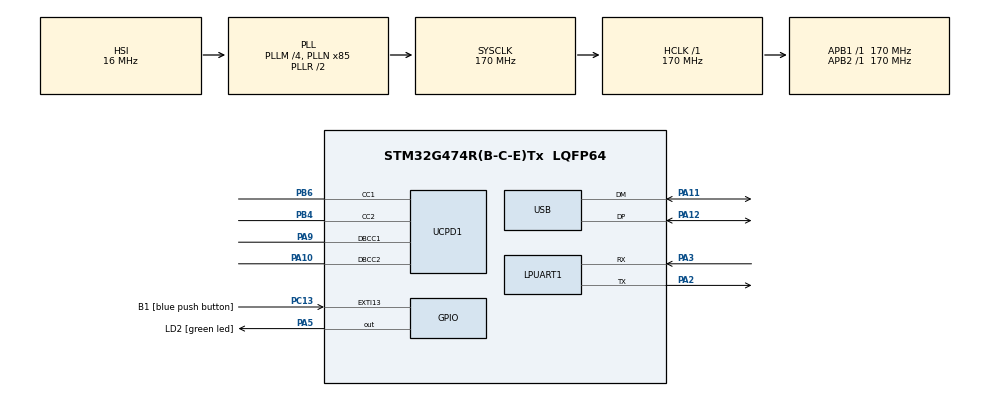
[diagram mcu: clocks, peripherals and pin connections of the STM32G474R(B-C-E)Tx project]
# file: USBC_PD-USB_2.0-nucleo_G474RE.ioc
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Dma.LPUART1_RX.3.Direction=DMA_PERIPH_TO_MEMORY
Dma.LPUART1_RX.3.EventEnable=DISABLE
Dma.LPUART1_RX.3.Instance=DMA1_Channel4
Dma.LPUART1_RX.3.MemDataAlignment=DMA_MDATAALIGN_BYTE
Dma.LPUART1_RX.3.MemInc=DMA_MINC_ENABLE
Dma.LPUART1_RX.3.Mode=DMA_NORMAL
Dma.LPUART1_RX.3.PeriphDataAlignment=DMA_PDATAALIGN_BYTE
Dma.LPUART1_RX.3.PeriphInc=DMA_PINC_DISABLE
Dma.LPUART1_RX.3.Polarity=HAL_DMAMUX_REQ_GEN_RISING
Dma.LPUART1_RX.3.Priority=DMA_PRIORITY_LOW
Dma.LPUART1_RX.3.RequestNumber=1
Dma.LPUART1_RX.3.SignalID=NONE
Dma.LPUART1_RX.3.SyncEnable=DISABLE
Dma.LPUART1_RX.3.SyncPolarity=HAL_DMAMUX_SYNC_NO_EVENT
Dma.LPUART1_RX.3.SyncRequestNumber=1
Dma.LPUART1_RX.3.SyncSignalID=NONE
Dma.LPUART1_TX.2.Direction=DMA_MEMORY_TO_PERIPH
Dma.LPUART1_TX.2.EventEnable=DISABLE
Dma.LPUART1_TX.2.Instance=DMA1_Channel3
Dma.LPUART1_TX.2.MemDataAlignment=DMA_MDATAALIGN_BYTE
Dma.LPUART1_TX.2.MemInc=DMA_MINC_ENABLE
Dma.LPUART1_TX.2.Mode=DMA_NORMAL
Dma.LPUART1_TX.2.PeriphDataAlignment=DMA_PDATAALIGN_BYTE
Dma.LPUART1_TX.2.PeriphInc=DMA_PINC_DISABLE
Dma.LPUART1_TX.2.Polarity=HAL_DMAMUX_REQ_GEN_RISING
Dma.LPUART1_TX.2.Priority=DMA_PRIORITY_LOW
Dma.LPUART1_TX.2.RequestNumber=1
Dma.LPUART1_TX.2.SignalID=NONE
Dma.LPUART1_TX.2.SyncEnable=DISABLE
Dma.LPUART1_TX.2.SyncPolarity=HAL_DMAMUX_SYNC_NO_EVENT
Dma.LPUART1_TX.2.SyncRequestNumber=1
Dma.LPUART1_TX.2.SyncSignalID=NONE
Dma.Request0=UCPD1_RX
Dma.Request1=UCPD1_TX
Dma.Request2=LPUART1_TX
Dma.Request3=LPUART1_RX
Dma.UCPD1_RX.0.Direction=DMA_PERIPH_TO_MEMORY
Dma.UCPD1_RX.0.EventEnable=DISABLE
Dma.UCPD1_RX.0.Instance=DMA1_Channel1
Dma.UCPD1_RX.0.MemDataAlignment=DMA_MDATAALIGN_BYTE
Dma.UCPD1_RX.0.MemInc=DMA_MINC_ENABLE
Dma.UCPD1_RX.0.Mode=DMA_NORMAL
Dma.UCPD1_RX.0.PeriphDataAlignment=DMA_PDATAALIGN_BYTE
Dma.UCPD1_RX.0.PeriphInc=DMA_PINC_DISABLE
Dma.UCPD1_RX.0.Polarity=HAL_DMAMUX_REQ_GEN_RISING
Dma.UCPD1_RX.0.Priority=DMA_PRIORITY_LOW
Dma.UCPD1_RX.0.RequestNumber=1
Dma.UCPD1_RX.0.SignalID=NONE
Dma.UCPD1_RX.0.SyncEnable=DISABLE
Dma.UCPD1_RX.0.SyncPolarity=HAL_DMAMUX_SYNC_NO_EVENT
Dma.UCPD1_RX.0.SyncRequestNumber=1
Dma.UCPD1_RX.0.SyncSignalID=NONE
Dma.UCPD1_TX.1.Direction=DMA_MEMORY_TO_PERIPH
Dma.UCPD1_TX.1.EventEnable=DISABLE
Dma.UCPD1_TX.1.Instance=DMA1_Channel2
Dma.UCPD1_TX.1.MemDataAlignment=DMA_MDATAALIGN_BYTE
Dma.UCPD1_TX.1.MemInc=DMA_MINC_ENABLE
Dma.UCPD1_TX.1.Mode=DMA_NORMAL
Dma.UCPD1_TX.1.PeriphDataAlignment=DMA_PDATAALIGN_BYTE
Dma.UCPD1_TX.1.PeriphInc=DMA_PINC_DISABLE
Dma.UCPD1_TX.1.Polarity=HAL_DMAMUX_REQ_GEN_RISING
Dma.UCPD1_TX.1.Priority=DMA_PRIORITY_LOW
Dma.UCPD1_TX.1.RequestNumber=1
Dma.UCPD1_TX.1.SignalID=NONE
Dma.UCPD1_TX.1.SyncEnable=DISABLE
Dma.UCPD1_TX.1.SyncPolarity=HAL_DMAMUX_SYNC_NO_EVENT
Dma.UCPD1_TX.1.SyncRequestNumber=1
Dma.UCPD1_TX.1.SyncSignalID=NONE
FREERTOS.Tasks01=defaultTask,24,128,StartDefaultTask,Default,NULL,Dynamic,NULL,NULL
FREERTOS.configLIBRARY_MAX_SYSCALL_INTERRUPT_PRIORITY=3
FREERTOS.configTOTAL_HEAP_SIZE=6144
FREERTOS.configUSE_NEWLIB_REENTRANT=1
GUI_INTERFACE.HWBoardVersionName=G474RE
GUI_INTERFACE.PDTypeName=Sink
Mcu.Family=STM32G4
Mcu.Name=STM32G474R(B-C-E)Tx
Mcu.Package=LQFP64
NVIC.DMA1_Channel1_IRQn=true\:3\:0\:false\:false\:true\:true\:false\:true
NVIC.DMA1_Channel2_IRQn=true\:3\:0\:false\:false\:true\:true\:false\:true
NVIC.DMA1_Channel3_IRQn=true\:3\:0\:false\:false\:true\:true\:false\:true
NVIC.DMA1_Channel4_IRQn=true\:3\:0\:false\:false\:true\:true\:false\:true
NVIC.EXTI15_10_IRQn=true\:3\:0\:false\:false\:true\:true\:true\:true
NVIC.LPUART1_IRQn=true\:3\:0\:false\:false\:true\:true\:true\:true
NVIC.PriorityGroup=NVIC_PRIORITYGROUP_4
NVIC.TIM6_DAC_IRQn=true\:4\:0\:true\:false\:true\:false\:false\:true
NVIC.TimeBase=TIM6_DAC_IRQn
NVIC.TimeBaseIP=TIM6
NVIC.UCPD1_IRQn=true\:3\:0\:false\:false\:true\:true\:true\:false
NVIC.USB_HP_IRQn=true\:3\:0\:false\:false\:true\:true\:true\:true
NVIC.USB_LP_IRQn=true\:3\:0\:false\:false\:true\:true\:false\:true
PA10.Mode=EnableDeadBattery
PA10.Signal=UCPD1_DBCC2
PA11.Mode=Device
PA11.Signal=USB_DM
PA12.Mode=Device
PA12.Signal=USB_DP
PA13.GPIO_Label=T_SWDIO
PA13.Mode=Serial_Wire
PA13.Signal=SYS_JTMS-SWDIO
PA14.GPIO_Label=T_SWCLK
PA14.Mode=Serial_Wire
PA14.Signal=SYS_JTCK-SWCLK
PA2.GPIO_Mode=GPIO_MODE_AF_PP
PA2.GPIO_PuPd=GPIO_NOPULL
PA2.GPIO_Speed=GPIO_SPEED_FREQ_LOW
PA2.Mode=Asynchronous
PA2.Signal=LPUART1_TX
PA3.GPIO_Mode=GPIO_MODE_AF_PP
PA3.GPIO_PuPd=GPIO_NOPULL
PA3.GPIO_Speed=GPIO_SPEED_FREQ_LOW
PA3.Mode=Asynchronous
PA3.Signal=LPUART1_RX
PA5.GPIO_Label=LD2 [green led]
PA5.Signal=GPIO_Output
PA9.Mode=EnableDeadBattery
PA9.Signal=UCPD1_DBCC1
PB3.GPIO_Label=T_SWO
PB3.Signal=SYS_JTDO-SWO
PB4.Mode=Sink_AllSignals
PB4.Signal=UCPD1_CC2
PB6.Mode=Sink_AllSignals
PB6.Signal=UCPD1_CC1
PC13.GPIO_Label=B1 [blue push button]
PC13.Signal=GPXTI13
PC14-OSC32_IN.Mode=LSE-External-Oscillator
PC14-OSC32_IN.Signal=RCC_OSC32_IN
PC15-OSC32_OUT.Mode=LSE-External-Oscillator
PC15-OSC32_OUT.Signal=RCC_OSC32_OUT
PF0-OSC_IN.Mode=HSE-External-Oscillator
PF0-OSC_IN.Signal=RCC_OSC_IN
PF1-OSC_OUT.Mode=HSE-External-Oscillator
PF1-OSC_OUT.Signal=RCC_OSC_OUT
ProjectManager.HeapSize=0x500
ProjectManager.StackSize=0x400
ProjectManager.TargetToolchain=STM32CubeIDE
RCC.ADC12Freq_Value=170000000
RCC.ADC345Freq_Value=170000000
RCC.AHBFreq_Value=170000000
RCC.APB1Freq_Value=170000000
RCC.APB1TimFreq_Value=170000000
RCC.APB2Freq_Value=170000000
RCC.APB2TimFreq_Value=170000000
RCC.CK48CLockSelection=RCC_USBCLKSOURCE_HSI48
RCC.CortexFreq_Value=170000000
RCC.EXTERNAL_CLOCK_VALUE=12288000
RCC.HCLKFreq_Value=170000000
RCC.HSE_VALUE=24000000
RCC.HSI48_VALUE=48000000
RCC.HSI_VALUE=16000000
RCC.PLLM=RCC_PLLM_DIV4
RCC.PLLN=85
RCC.RTCClockSelection=RCC_RTCCLKSOURCE_LSE
RCC.SYSCLKFreq_VALUE=170000000
RCC.SYSCLKSource=RCC_SYSCLKSOURCE_PLLCLK
RCC.USBFreq_Value=48000000
RCC.VCOOutputFreq_Value=340000000
USBPD.Is_GetStatus_Supported_P0=USBPD_FALSE
USBPD.PE_SpecRevision_P0=USBPD_SPECIFICATION_REV3
USB_DEVICE.CLASS_NAME_FS=CDC
USB_DEVICE.VirtualMode=Cdc
USB_DEVICE.VirtualModeFS=Cdc_FS
VP_FREERTOS_VS_CMSIS_V2.Mode=CMSIS_V2
VP_GUI_INTERFACE_VS_gui_interface.Mode=GUI_INTERFACE
VP_SYS_VS_DBSignals.Mode=DisableDeadBatterySignals
VP_SYS_VS_tim6.Mode=TIM6
VP_TRACER_EMB_VS_traceremb_lpuart1.Mode=TRACER_EMB_LPUART1
VP_USBPD_VS_PD3FULL.Mode=PD3_Full_Stack
VP_USBPD_VS_USBPD1.Mode=USBPD_P0
VP_USBPD_VS_usbpd_tim1.Mode=TIM1
VP_USBPD_VS_usbpd_traceremb.Mode=TRACER_EMB
VP_USB_DEVICE_VS_USB_DEVICE_CDC_FS.Mode=CDC_FS
board=NUCLEO-G474RE

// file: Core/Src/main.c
/* USER CODE BEGIN Header */
/**
  ******************************************************************************
  * @file           : main.c
  * @brief          : Main program body
  ******************************************************************************
  * @attention
  *
  * <h2><center>&copy; Copyright (c) 2021 STMicroelectronics.
  * All rights reserved.</center></h2>
  *
  * This software component is licensed by ST under BSD 3-Clause license,
  * the "License"; You may not use this file except in compliance with the
  * License. You may obtain a copy of the License at:
  *                        opensource.org/licenses/BSD-3-Clause
  *
  ******************************************************************************
  */
/* USER CODE END Header */
#include "main.h"
#include "cmsis_os.h"
#include "usbpd.h"
#include "usb_device.h"
#include "usb_device.h"

/* USER CODE BEGIN Includes */

#include "usbd_cdc_if.h"

/* USER CODE END Includes */

/* Definitions for defaultTask */
osThreadId_t defaultTaskHandle;
const osThreadAttr_t defaultTask_attributes = {
  .name = "defaultTask",
  .priority = (osPriority_t) osPriorityNormal,
  .stack_size = 128 * 4
};

void SystemClock_Config(void);
static void MX_GPIO_Init(void);
static void MX_LPUART1_UART_Init(void);
static void MX_DMA_Init(void);
static void MX_UCPD1_Init(void);
void StartDefaultTask(void *argument);

int main(void)
{

  /* MCU Configuration--------------------------------------------------------*/

  /* Reset of all peripherals, Initializes the Flash interface and the Systick. */
  HAL_Init();

  /* Configure the system clock */
  SystemClock_Config();

  /* Initialize all configured peripherals */
  MX_GPIO_Init();
  MX_LPUART1_UART_Init();
  MX_DMA_Init();
  MX_UCPD1_Init();
  MX_USB_Device_Init();

  /* Init scheduler */
  osKernelInitialize();
  /* USBPD initialisation ---------------------------------*/
  MX_USBPD_Init();

  /* Create the thread(s) */
  /* creation of defaultTask */
  defaultTaskHandle = osThreadNew(StartDefaultTask, NULL, &defaultTask_attributes);

  /* Start scheduler */
  osKernelStart();

  /* We should never get here as control is now taken by the scheduler */
  /* Infinite loop */
  while (1)
  {

  }
}

void SystemClock_Config(void)
{
  RCC_OscInitTypeDef RCC_OscInitStruct = {0};
  RCC_ClkInitTypeDef RCC_ClkInitStruct = {0};
  RCC_PeriphCLKInitTypeDef PeriphClkInit = {0};

  /** Configure the main internal regulator output voltage
  */
  HAL_PWREx_ControlVoltageScaling(PWR_REGULATOR_VOLTAGE_SCALE1_BOOST);
  /** Initializes the RCC Oscillators according to the specified parameters
  * in the RCC_OscInitTypeDef structure.
  */
  RCC_OscInitStruct.OscillatorType = RCC_OSCILLATORTYPE_HSI|RCC_OSCILLATORTYPE_HSI48;
  RCC_OscInitStruct.HSIState = RCC_HSI_ON;
  RCC_OscInitStruct.HSICalibrationValue = RCC_HSICALIBRATION_DEFAULT;
  RCC_OscInitStruct.HSI48State = RCC_HSI48_ON;
  RCC_OscInitStruct.PLL.PLLState = RCC_PLL_ON;
  RCC_OscInitStruct.PLL.PLLSource = RCC_PLLSOURCE_HSI;
  RCC_OscInitStruct.PLL.PLLM = RCC_PLLM_DIV4;
  RCC_OscInitStruct.PLL.PLLN = 85;
  RCC_OscInitStruct.PLL.PLLP = RCC_PLLP_DIV2;
  RCC_OscInitStruct.PLL.PLLQ = RCC_PLLQ_DIV2;
  RCC_OscInitStruct.PLL.PLLR = RCC_PLLR_DIV2;
  if (HAL_RCC_OscConfig(&RCC_OscInitStruct) != HAL_OK)
  {
    Error_Handler();
  }
  /** Initializes the CPU, AHB and APB buses clocks
  */
  RCC_ClkInitStruct.ClockType = RCC_CLOCKTYPE_HCLK|RCC_CLOCKTYPE_SYSCLK
                              |RCC_CLOCKTYPE_PCLK1|RCC_CLOCKTYPE_PCLK2;
  RCC_ClkInitStruct.SYSCLKSource = RCC_SYSCLKSOURCE_PLLCLK;
  RCC_ClkInitStruct.AHBCLKDivider = RCC_SYSCLK_DIV1;
  RCC_ClkInitStruct.APB1CLKDivider = RCC_HCLK_DIV1;
  RCC_ClkInitStruct.APB2CLKDivider = RCC_HCLK_DIV1;

  if (HAL_RCC_ClockConfig(&RCC_ClkInitStruct, FLASH_LATENCY_4) != HAL_OK)
  {
    Error_Handler();
  }
  /** Initializes the peripherals clocks
  */
  PeriphClkInit.PeriphClockSelection = RCC_PERIPHCLK_LPUART1|RCC_PERIPHCLK_USB;
  PeriphClkInit.Lpuart1ClockSelection = RCC_LPUART1CLKSOURCE_PCLK1;
  PeriphClkInit.UsbClockSelection = RCC_USBCLKSOURCE_HSI48;
  if (HAL_RCCEx_PeriphCLKConfig(&PeriphClkInit) != HAL_OK)
  {
    Error_Handler();
  }
}

static void MX_LPUART1_UART_Init(void)
{

  LL_LPUART_InitTypeDef LPUART_InitStruct = {0};

  LL_GPIO_InitTypeDef GPIO_InitStruct = {0};

  /* Peripheral clock enable */
  LL_APB1_GRP2_EnableClock(LL_APB1_GRP2_PERIPH_LPUART1);

  LL_AHB2_GRP1_EnableClock(LL_AHB2_GRP1_PERIPH_GPIOA);
  /**LPUART1 GPIO Configuration
  PA2   ------> LPUART1_TX
  PA3   ------> LPUART1_RX
  */
  GPIO_InitStruct.Pin = LL_GPIO_PIN_2;
  GPIO_InitStruct.Mode = LL_GPIO_MODE_ALTERNATE;
  GPIO_InitStruct.Speed = LL_GPIO_SPEED_FREQ_LOW;
  GPIO_InitStruct.OutputType = LL_GPIO_OUTPUT_PUSHPULL;
  GPIO_InitStruct.Pull = LL_GPIO_PULL_NO;
  GPIO_InitStruct.Alternate = LL_GPIO_AF_12;
  LL_GPIO_Init(GPIOA, &GPIO_InitStruct);

  GPIO_InitStruct.Pin = LL_GPIO_PIN_3;
  GPIO_InitStruct.Mode = LL_GPIO_MODE_ALTERNATE;
  GPIO_InitStruct.Speed = LL_GPIO_SPEED_FREQ_LOW;
  GPIO_InitStruct.OutputType = LL_GPIO_OUTPUT_PUSHPULL;
  GPIO_InitStruct.Pull = LL_GPIO_PULL_NO;
  GPIO_InitStruct.Alternate = LL_GPIO_AF_12;
  LL_GPIO_Init(GPIOA, &GPIO_InitStruct);

  /* LPUART1 DMA Init */

  /* LPUART1_TX Init */
  LL_DMA_SetPeriphRequest(DMA1, LL_DMA_CHANNEL_3, LL_DMAMUX_REQ_LPUART1_TX);

  LL_DMA_SetDataTransferDirection(DMA1, LL_DMA_CHANNEL_3, LL_DMA_DIRECTION_MEMORY_TO_PERIPH);

  LL_DMA_SetChannelPriorityLevel(DMA1, LL_DMA_CHANNEL_3, LL_DMA_PRIORITY_LOW);

  LL_DMA_SetMode(DMA1, LL_DMA_CHANNEL_3, LL_DMA_MODE_NORMAL);

  LL_DMA_SetPeriphIncMode(DMA1, LL_DMA_CHANNEL_3, LL_DMA_PERIPH_NOINCREMENT);

  LL_DMA_SetMemoryIncMode(DMA1, LL_DMA_CHANNEL_3, LL_DMA_MEMORY_INCREMENT);

  LL_DMA_SetPeriphSize(DMA1, LL_DMA_CHANNEL_3, LL_DMA_PDATAALIGN_BYTE);

  LL_DMA_SetMemorySize(DMA1, LL_DMA_CHANNEL_3, LL_DMA_MDATAALIGN_BYTE);

  /* LPUART1_RX Init */
  LL_DMA_SetPeriphRequest(DMA1, LL_DMA_CHANNEL_4, LL_DMAMUX_REQ_LPUART1_RX);

  LL_DMA_SetDataTransferDirection(DMA1, LL_DMA_CHANNEL_4, LL_DMA_DIRECTION_PERIPH_TO_MEMORY);

  LL_DMA_SetChannelPriorityLevel(DMA1, LL_DMA_CHANNEL_4, LL_DMA_PRIORITY_LOW);

  LL_DMA_SetMode(DMA1, LL_DMA_CHANNEL_4, LL_DMA_MODE_NORMAL);

  LL_DMA_SetPeriphIncMode(DMA1, LL_DMA_CHANNEL_4, LL_DMA_PERIPH_NOINCREMENT);

  LL_DMA_SetMemoryIncMode(DMA1, LL_DMA_CHANNEL_4, LL_DMA_MEMORY_INCREMENT);

  LL_DMA_SetPeriphSize(DMA1, LL_DMA_CHANNEL_4, LL_DMA_PDATAALIGN_BYTE);

  LL_DMA_SetMemorySize(DMA1, LL_DMA_CHANNEL_4, LL_DMA_MDATAALIGN_BYTE);

  /* LPUART1 interrupt Init */
  NVIC_SetPriority(LPUART1_IRQn, NVIC_EncodePriority(NVIC_GetPriorityGrouping(),3, 0));
  NVIC_EnableIRQ(LPUART1_IRQn);

  LPUART_InitStruct.PrescalerValue = LL_LPUART_PRESCALER_DIV1;
  LPUART_InitStruct.BaudRate = 921600;
  LPUART_InitStruct.DataWidth = LL_LPUART_DATAWIDTH_8B;
  LPUART_InitStruct.StopBits = LL_LPUART_STOPBITS_1;
  LPUART_InitStruct.Parity = LL_LPUART_PARITY_NONE;
  LPUART_InitStruct.TransferDirection = LL_LPUART_DIRECTION_TX_RX;
  LPUART_InitStruct.HardwareFlowControl = LL_LPUART_HWCONTROL_NONE;
  LL_LPUART_Init(LPUART1, &LPUART_InitStruct);
  LL_LPUART_SetTXFIFOThreshold(LPUART1, LL_LPUART_FIFOTHRESHOLD_1_8);
  LL_LPUART_SetRXFIFOThreshold(LPUART1, LL_LPUART_FIFOTHRESHOLD_1_8);
  LL_LPUART_DisableFIFO(LPUART1);

  LL_LPUART_Enable(LPUART1);

  /* Polling LPUART1 initialisation */
  while((!(LL_LPUART_IsActiveFlag_TEACK(LPUART1))) || (!(LL_LPUART_IsActiveFlag_REACK(LPUART1))))
  {
  }

}

static void MX_UCPD1_Init(void)
{

  LL_GPIO_InitTypeDef GPIO_InitStruct = {0};

  /* Peripheral clock enable */
  LL_APB1_GRP2_EnableClock(LL_APB1_GRP2_PERIPH_UCPD1);

  LL_AHB2_GRP1_EnableClock(LL_AHB2_GRP1_PERIPH_GPIOB);
  /**UCPD1 GPIO Configuration
  PB4   ------> UCPD1_CC2
  PB6   ------> UCPD1_CC1
  */
  GPIO_InitStruct.Pin = LL_GPIO_PIN_4;
  GPIO_InitStruct.Mode = LL_GPIO_MODE_ANALOG;
  GPIO_InitStruct.Pull = LL_GPIO_PULL_NO;
  LL_GPIO_Init(GPIOB, &GPIO_InitStruct);

  GPIO_InitStruct.Pin = LL_GPIO_PIN_6;
  GPIO_InitStruct.Mode = LL_GPIO_MODE_ANALOG;
  GPIO_InitStruct.Pull = LL_GPIO_PULL_NO;
  LL_GPIO_Init(GPIOB, &GPIO_InitStruct);

  /* UCPD1 DMA Init */

  /* UCPD1_RX Init */
  LL_DMA_SetPeriphRequest(DMA1, LL_DMA_CHANNEL_1, LL_DMAMUX_REQ_UCPD1_RX);

  LL_DMA_SetDataTransferDirection(DMA1, LL_DMA_CHANNEL_1, LL_DMA_DIRECTION_PERIPH_TO_MEMORY);

  LL_DMA_SetChannelPriorityLevel(DMA1, LL_DMA_CHANNEL_1, LL_DMA_PRIORITY_LOW);

  LL_DMA_SetMode(DMA1, LL_DMA_CHANNEL_1, LL_DMA_MODE_NORMAL);

  LL_DMA_SetPeriphIncMode(DMA1, LL_DMA_CHANNEL_1, LL_DMA_PERIPH_NOINCREMENT);

  LL_DMA_SetMemoryIncMode(DMA1, LL_DMA_CHANNEL_1, LL_DMA_MEMORY_INCREMENT);

  LL_DMA_SetPeriphSize(DMA1, LL_DMA_CHANNEL_1, LL_DMA_PDATAALIGN_BYTE);

  LL_DMA_SetMemorySize(DMA1, LL_DMA_CHANNEL_1, LL_DMA_MDATAALIGN_BYTE);

  /* UCPD1_TX Init */
  LL_DMA_SetPeriphRequest(DMA1, LL_DMA_CHANNEL_2, LL_DMAMUX_REQ_UCPD1_TX);

  LL_DMA_SetDataTransferDirection(DMA1, LL_DMA_CHANNEL_2, LL_DMA_DIRECTION_MEMORY_TO_PERIPH);

  LL_DMA_SetChannelPriorityLevel(DMA1, LL_DMA_CHANNEL_2, LL_DMA_PRIORITY_LOW);

  LL_DMA_SetMode(DMA1, LL_DMA_CHANNEL_2, LL_DMA_MODE_NORMAL);

  LL_DMA_SetPeriphIncMode(DMA1, LL_DMA_CHANNEL_2, LL_DMA_PERIPH_NOINCREMENT);

  LL_DMA_SetMemoryIncMode(DMA1, LL_DMA_CHANNEL_2, LL_DMA_MEMORY_INCREMENT);

  LL_DMA_SetPeriphSize(DMA1, LL_DMA_CHANNEL_2, LL_DMA_PDATAALIGN_BYTE);

  LL_DMA_SetMemorySize(DMA1, LL_DMA_CHANNEL_2, LL_DMA_MDATAALIGN_BYTE);

  /* UCPD1 interrupt Init */
  NVIC_SetPriority(UCPD1_IRQn, NVIC_EncodePriority(NVIC_GetPriorityGrouping(),3, 0));
  NVIC_EnableIRQ(UCPD1_IRQn);

}

static void MX_DMA_Init(void)
{

  /* DMA controller clock enable */
  __HAL_RCC_DMAMUX1_CLK_ENABLE();
  __HAL_RCC_DMA1_CLK_ENABLE();

  /* DMA interrupt init */
  /* DMA1_Channel1_IRQn interrupt configuration */
  NVIC_SetPriority(DMA1_Channel1_IRQn, NVIC_EncodePriority(NVIC_GetPriorityGrouping(),3, 0));
  NVIC_EnableIRQ(DMA1_Channel1_IRQn);
  /* DMA1_Channel2_IRQn interrupt configuration */
  NVIC_SetPriority(DMA1_Channel2_IRQn, NVIC_EncodePriority(NVIC_GetPriorityGrouping(),3, 0));
  NVIC_EnableIRQ(DMA1_Channel2_IRQn);
  /* DMA1_Channel3_IRQn interrupt configuration */
  NVIC_SetPriority(DMA1_Channel3_IRQn, NVIC_EncodePriority(NVIC_GetPriorityGrouping(),3, 0));
  NVIC_EnableIRQ(DMA1_Channel3_IRQn);
  /* DMA1_Channel4_IRQn interrupt configuration */
  NVIC_SetPriority(DMA1_Channel4_IRQn, NVIC_EncodePriority(NVIC_GetPriorityGrouping(),3, 0));
  NVIC_EnableIRQ(DMA1_Channel4_IRQn);

}

static void MX_GPIO_Init(void)
{
  GPIO_InitTypeDef GPIO_InitStruct = {0};

  /* GPIO Ports Clock Enable */
  __HAL_RCC_GPIOC_CLK_ENABLE();
  __HAL_RCC_GPIOF_CLK_ENABLE();
  __HAL_RCC_GPIOA_CLK_ENABLE();
  __HAL_RCC_GPIOB_CLK_ENABLE();

  /*Configure GPIO pin Output Level */
  HAL_GPIO_WritePin(LD2_GPIO_Port, LD2_Pin, GPIO_PIN_RESET);

  /*Configure GPIO pin : B1_Pin */
  GPIO_InitStruct.Pin = B1_Pin;
  GPIO_InitStruct.Mode = GPIO_MODE_IT_RISING;
  GPIO_InitStruct.Pull = GPIO_NOPULL;
  HAL_GPIO_Init(B1_GPIO_Port, &GPIO_InitStruct);

  /*Configure GPIO pin : LD2_Pin */
  GPIO_InitStruct.Pin = LD2_Pin;
  GPIO_InitStruct.Mode = GPIO_MODE_OUTPUT_PP;
  GPIO_InitStruct.Pull = GPIO_NOPULL;
  GPIO_InitStruct.Speed = GPIO_SPEED_FREQ_LOW;
  HAL_GPIO_Init(LD2_GPIO_Port, &GPIO_InitStruct);

  /* EXTI interrupt init*/
  HAL_NVIC_SetPriority(EXTI15_10_IRQn, 3, 0);
  HAL_NVIC_EnableIRQ(EXTI15_10_IRQn);

}

void StartDefaultTask(void *argument)
{
  /* USER CODE BEGIN 5 */
  /* Infinite loop */
  for(;;)
  {
	CDC_Transmit_FS("TEST\r\n", 6);
    osDelay(1000);
  }
  /* USER CODE END 5 */
}

void HAL_TIM_PeriodElapsedCallback(TIM_HandleTypeDef *htim)
{
  if (htim->Instance == TIM6) {
    HAL_IncTick();
  }
  /* USER CODE BEGIN Callback 1 */
#ifdef _GUI_INTERFACE
  if (htim->Instance == TIM6) {
	  GUI_TimerCounter();
  }
#endif
  /* USER CODE END Callback 1 */
}

void Error_Handler(void)
{
  __disable_irq();
  while (1)
  {
  }
}

/************************ (C) COPYRIGHT STMicroelectronics *****END OF FILE****/
